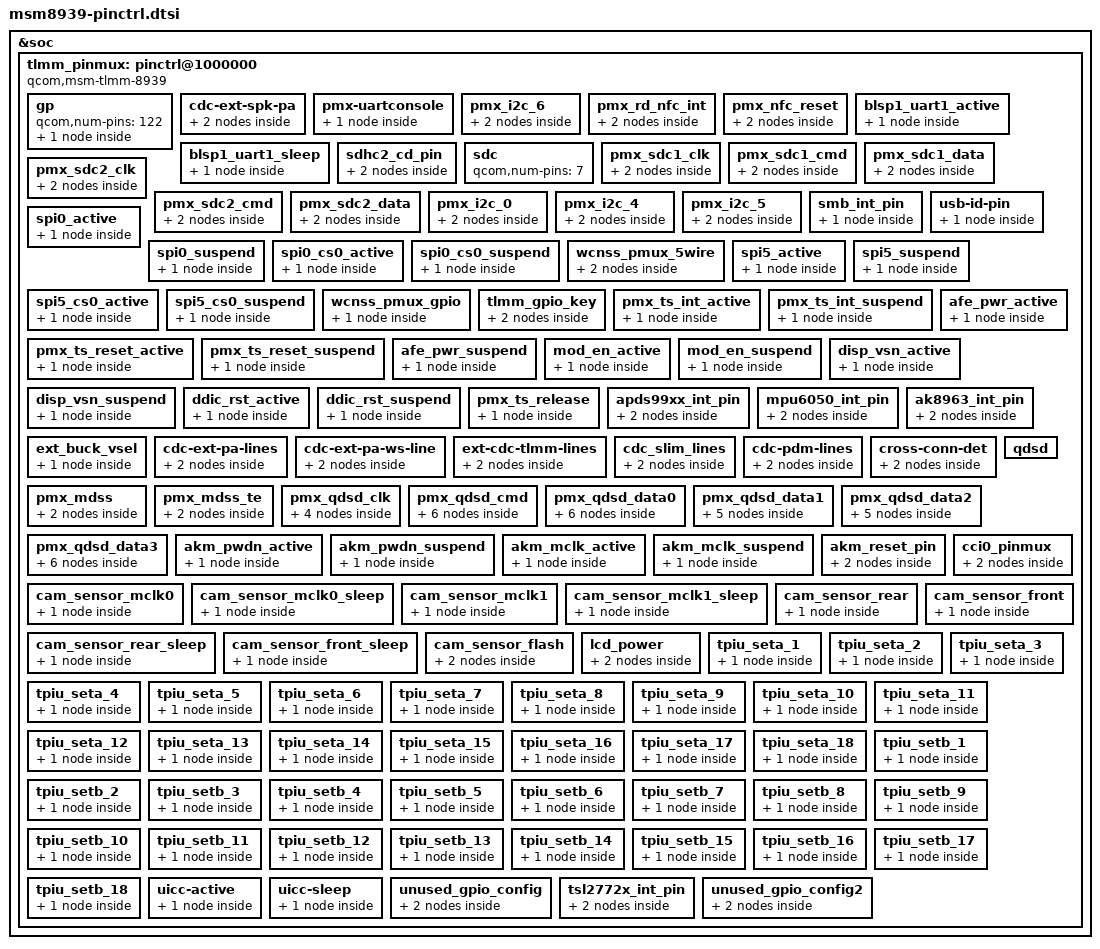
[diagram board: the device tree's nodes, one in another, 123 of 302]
/* Copyright (c) 2014-2015, The Linux Foundation. All rights reserved.
 *
 * This program is free software; you can redistribute it and/or modify
 * it under the terms of the GNU General Public License version 2 and
 * only version 2 as published by the Free Software Foundation.
 *
 * This program is distributed in the hope that it will be useful,
 * but WITHOUT ANY WARRANTY; without even the implied warranty of
 * MERCHANTABILITY or FITNESS FOR A PARTICULAR PURPOSE.  See the
 * GNU General Public License for more details.
 */

&soc {
	tlmm_pinmux: pinctrl@1000000 {
		compatible = "qcom,msm-tlmm-8939", "qcom,msm-tlmm-8916";
		reg = <0x1000000 0x300000>;
		interrupts = <0 208 0>;

		/*General purpose pins*/
		gp: gp {
			qcom,num-pins = <122>;
			#qcom,pin-cells = <1>;
			msm_gpio: msm_gpio {
				compatible = "qcom,msm-tlmm-gp";
				gpio-controller;
				#gpio-cells = <2>;
				interrupt-controller;
				#interrupt-cells = <2>;
				num_irqs = <122>;
			};
		};

		cdc-ext-spk-pa {
			qcom,pins = <&gp 0>;
			qcom,num-grp-pins = <1>;
			qcom,pin-func = <0>;
			label = "cdc-ext-spk-pa";
			cdc_ext_spk_pa_act: ext_spk_pa_on {
				drive-strength = <8>;
				output-low;
				bias-pull-none;
			};
			cdc_ext_spk_pa_sus: ext_spk_pa_off {
				drive-strength = <2>;
				bias-disable;
			};
		};

		pmx-uartconsole {
			qcom,pins = <&gp 4>, <&gp 5>;
			qcom,num-grp-pins = <2>;
			qcom,pin-func = <2>;
			label = "uart-console";
			uart_console_sleep: uart-console {
				drive-strength = <2>;
				bias-pull-down;
			};
		};

		pmx_i2c_6 {
			/* CLK, DATA */
			qcom,pins = <&gp 22>, <&gp 23>;
			qcom,num-grp-pins = <2>;
			qcom,pin-func = <2>;
			label = "pmx_i2c_6";
			/* active state */
			i2c_6_active: i2c_6_active{
				drive-strength = <2>; /* 2 MA */
				bias-disable; /* No PULL */
			};
			/* suspended state */
			i2c_6_sleep: i2c_6_sleep {
				drive-strength = <2>; /* 2 MA */
				bias-disable; /* No PULL */
			};
		};

		pmx_rd_nfc_int{
			qcom,pins = <&gp 21>;
			qcom,pin-func = <0>;
			qcom,num-grp-pins = <1>;
			label = "pmx_nfc_int";

			nfc_int_active: active {
				drive-strength = <6>;
				bias-pull-up;
			};

			nfc_int_suspend: suspend {
				drive-strength = <6>;
				bias-pull-up;
			};
		};

		pmx_nfc_reset{
			qcom,pins = <&gp 20>;
			qcom,pin-func = <0>;
			qcom,num-grp-pins = <1>;
			label = "pmx_nfc_disable";

			nfc_disable_active: active {
				drive-strength = <6>;
				bias-pull-up;
			};

			nfc_disable_suspend: suspend {
				drive-strength = <6>;
				bias-disable;
			};
		};

		blsp1_uart1_active {
			qcom,pins = <&gp 0>, <&gp 1>, <&gp 2>, <&gp 3>;
			qcom,num-grp-pins = <4>;
			qcom,pin-func = <2>;
			label = "blsp1_uart1_active";

			hsuart_active: default {
			        drive-strength = <16>;
			        bias-disable;
			};
		};

		blsp1_uart1_sleep {
			qcom,pins = <&gp 0>, <&gp 1>, <&gp 2>, <&gp 3>;
			qcom,num-grp-pins = <4>;
			qcom,pin-func = <0>;
			label = "blsp1_uart1_sleep";

			hsuart_sleep: sleep {
			        drive-strength = <2>;
			        bias-disable;
			};
		};

		sdhc2_cd_pin {
			qcom,pins = <&gp 38>;
			qcom,num-grp-pins = <1>;
			qcom,pin-func = <0>;
			label = "cd-gpio";
			sdc2_cd_on: cd_on {
				drive-strength = <2>;
				bias-pull-up;/* [PLATFORM]-MOD by TCTNB.YuBin, idol3 ds sd_cd_pin float need to pull up */
			};
			sdc2_cd_off: cd_off {
				drive-strength = <2>;
				bias-pull-up;/* [PLATFORM]-MOD by TCTNB.YuBin, idol3 ds sd_cd_pin float need to pull up */
			};
		};

		/* SDC pin type */
		sdc: sdc {
			/* 0-2 for sdc1 4-6 for sdc2 */
			qcom,num-pins = <7>;
			/* Order of pins */
			/* SDC1: CLK -> 0, CMD -> 1, DATA -> 2 */
			/* SDC2: CLK -> 4, CMD -> 5, DATA -> 6 */
			#qcom,pin-cells = <1>;
		};

		pmx_sdc1_clk {
			qcom,pins = <&sdc 0>;
			qcom,num-grp-pins = <1>;
			label = "sdc1-clk";
			sdc1_clk_on: clk_on {
				bias-disable; /* NO pull */
				drive-strength = <16>; /* 16 MA */
			};
			sdc1_clk_off: clk_off {
				bias-disable; /* NO pull */
				drive-strength = <2>; /* 2 MA */
			};
		};

		pmx_sdc1_cmd {
			qcom,pins = <&sdc 1>;
			qcom,num-grp-pins = <1>;
			label = "sdc1-cmd";
			sdc1_cmd_on: cmd_on {
				bias-pull-up; /* pull up */
				drive-strength = <10>; /* 10 MA */
			};
			sdc1_cmd_off: cmd_off {
				bias-pull-up; /* pull up */
				drive-strength = <2>; /* 2 MA */
			};
		};

		pmx_sdc1_data {
			qcom,pins = <&sdc 2>;
			qcom,num-grp-pins = <1>;
			label = "sdc1-data";
			sdc1_data_on: data_on {
				bias-pull-up; /* pull up */
				drive-strength = <10>; /* 10 MA */
			};
			sdc1_data_off: data_off {
				bias-pull-up; /* pull up */
				drive-strength = <2>; /* 2 MA */
			};
		};

		pmx_sdc2_clk {
			qcom,pins = <&sdc 4>;
			qcom,num-grp-pins = <1>;
			label = "sdc2-clk";
			sdc2_clk_on: clk_on {
				bias-disable; /* NO pull */
				drive-strength = <16>; /* 16 MA */
			};
			sdc2_clk_off: clk_off {
				bias-disable; /* NO pull */
				drive-strength = <2>; /* 2 MA */
			};
		};

		pmx_sdc2_cmd {
			qcom,pins = <&sdc 5>;
			qcom,num-grp-pins = <1>;
			label = "sdc2-cmd";
			sdc2_cmd_on: cmd_on {
				bias-pull-up; /* pull up */
				drive-strength = <10>; /* 10 MA */
			};
			sdc2_cmd_off: cmd_off {
				bias-pull-up; /* pull up */
				drive-strength = <2>; /* 2 MA */
			};
		};

		pmx_sdc2_data {
			qcom,pins = <&sdc 6>;
			qcom,num-grp-pins = <1>;
			label = "sdc2-data";
			sdc2_data_on: data_on {
				bias-pull-up; /* pull up */
				drive-strength = <10>; /* 10 MA */
			};
			sdc2_data_off: data_off {
				bias-pull-up; /* pull up */
				drive-strength = <2>; /* 2 MA */
			};
		};
		pmx_i2c_0 {
			/* CLK, DATA */
			qcom,pins = <&gp 7>, <&gp 6>;
			qcom,num-grp-pins = <2>;
			qcom,pin-func = <3>;
			label = "pmx_i2c_0";

			i2c_0_active: i2c_0_active {
				drive-strength = <2>; /* 2 MA */
				bias-disable;         /* No PULL */
			};

			i2c_0_sleep: i2c_0_sleep {
				drive-strength = <2>; /* 2 MA */
				bias-disable;	      /* No PULL */
			};
		};

		pmx_i2c_4 {
			qcom,pins = <&gp 14>, <&gp 15>; /* SDA, SCL */
			qcom,num-grp-pins = <2>;
			qcom,pin-func = <2>;
			label = "pmx_i2c_4";

			i2c_4_active: i2c_4_active {
				drive-strength = <2>;
				bias-disable;
			};

			i2c_4_sleep: i2c_4_sleep {
				drive-strength = <2>;
				bias-disable;
			};
		};

		pmx_i2c_5 {
			qcom,pins = <&gp 18>, <&gp 19>; /* SDA, SCL */
			qcom,num-grp-pins = <2>;
			qcom,pin-func = <2>;
			label = "pmx_i2c_5";

			i2c_5_active: i2c_5_active {
				drive-strength = <2>;
				bias-disable;
			};

			i2c_5_sleep: i2c_5_sleep {
				drive-strength = <2>;
				bias-disable;
			};
		};

		smb_int_pin {
			qcom,pins = <&gp 62>;
			qcom,num-grp-pins = <1>;
			qcom,pin-func = <0>;
			label = "smb1360_int_gpio";
			smb_int_default: smb_int_default {
				drive-strength = <2>;	/* 2 MA */
				bias-pull-up;		/* PULL UP*/
			};
		};

		usb-id-pin {
                        /*[PLATFORM]-Mod-BEGIN by TCTNB.Bin.Su, PR-883930, 2014/12/30, Idle power consumption is high in airplane*/
			//qcom,pins = <&gp 79>;/*NB.THW modify 2014/11/17*/
                        qcom,pins = <&gp 69>;
                        /* [PLATFORM]-Mod-END by TCTNB.Bin.Su */
			qcom,num-grp-pins = <1>;
			qcom,pin-func = <0>;
			label = "usb-id-pin";
			usbid_default: default {
				drive-strength = <8>;
				bias-pull-up;
			};
		};

		 spi0_active {
                        /* MOSI, MISO, CLK */
                        qcom,pins = <&gp 8>, <&gp 9>, <&gp 11>;
                        qcom,num-grp-pins = <3>;
                        qcom,pin-func = <1>;
                        label = "spi0-active";
                        /* active state */
                        spi0_default: spi0_default {
                                drive-strength = <12>; /* 12 MA */
                                bias-disable = <0>; /* No PULL */
                        };
                };

                spi0_suspend {
                        /* MOSI, MISO, CLK */
                        qcom,pins = <&gp 8>, <&gp 9>, <&gp 11>;
                        qcom,num-grp-pins = <3>;
                        qcom,pin-func = <0>;
                        label = "spi0-suspend";
                        /* suspended state */
                        spi0_sleep: spi0_sleep {
                                drive-strength = <2>; /* 2 MA */
			        bias-pull-down; /* PULL Down */
                        };
                };

                spi0_cs0_active {
                        /* CS */
                        qcom,pins = <&gp 10>;
                        qcom,num-grp-pins = <1>;
                        qcom,pin-func = <1>;
                        label = "spi0-cs0-active";
                        spi0_cs0_active: cs0_active {
                                drive-strength = <2>;
                                bias-disable = <0>;
                        };
                };

                spi0_cs0_suspend {
                        /* CS */
                        qcom,pins = <&gp 10>;
                        qcom,num-grp-pins = <1>;
                        qcom,pin-func = <0>;
                        label = "spi0-cs0-suspend";
                        spi0_cs0_sleep: cs0_sleep {
                                drive-strength = <2>;
                                bias-disable = <0>;
                        };
                };

		wcnss_pmux_5wire: wcnss_pmux_5wire {
			/* Uses general purpose pins */
			qcom,pins = <&gp 40>, <&gp 41>,
				    <&gp 42>, <&gp 43>,
				    <&gp 44>;
			qcom,num-grp-pins = <5>;
			qcom,pin-func = <1>;
			label = "wcnss_5wire_pins";
			/* Active configuration of bus pins */
			wcnss_default: wcnss_default {
			        drive-strength = <6>; /* 6 MA */
			        bias-pull-up; /* PULL UP */
			};
			wcnss_sleep: wcnss_sleep {
			        drive-strength = <2>; /* 2 MA */
			        bias-pull-down; /* PULL Down */
			};
		};

		spi5_active {
                        /* MOSI, MISO, CLK */
                        qcom,pins = <&gp 16>, <&gp 17>, <&gp 19>;
                        qcom,num-grp-pins = <3>;
                        qcom,pin-func = <1>;
                        label = "spi5-active";
                        /* active state */
                        spi5_default: spi5_default {
                                drive-strength = <16>; /* 16 MA */
                                bias-disable = <0>; /* No PULL */
                        };
                };

                spi5_suspend {
                        /* MOSI, MISO, CLK */
                        qcom,pins = <&gp 16>, <&gp 17>, <&gp 19>;
                        qcom,num-grp-pins = <3>;
                        qcom,pin-func = <0>;
                        label = "spi5-suspend";
                        /* suspended state */
                        spi5_sleep: spi5_sleep {
                                drive-strength = <2>; /* 2 MA */
                                bias-disable = <0>; /* No PULL */
                        };
                };

                spi5_cs0_active {
                        /* CS */
                        qcom,pins = <&gp 18>;
                        qcom,num-grp-pins = <1>;
                        qcom,pin-func = <1>;
                        label = "spi5-cs0-active";
                        spi5_cs0_active: cs0_active {
                                drive-strength = <2>;
                                bias-disable = <0>;
                        };
                };

                spi5_cs0_suspend {
                        /* CS */
                        qcom,pins = <&gp 18>;
                        qcom,num-grp-pins = <1>;
                        qcom,pin-func = <0>;
                        label = "spi5-cs0-suspend";
                        spi5_cs0_sleep: cs0_sleep {
                                drive-strength = <2>;
                                bias-disable = <0>;
                        };
                };

		wcnss_pmux_gpio: wcnss_pmux_gpio {
			/* Uses general purpose pins */
			qcom,pins = <&gp 40>, <&gp 41>,
				    <&gp 42>, <&gp 43>,
				    <&gp 44>;
			qcom,num-grp-pins = <5>;
			qcom,pin-func = <0>;
			label = "wcnss_5gpio_pins";
			/* Active configuration of bus pins */
			wcnss_gpio_default: wcnss_gpio_default {
			        drive-strength = <6>; /* 6 MA */
			        bias-pull-up; /* PULL UP */
			};
		};

		tlmm_gpio_key {
			qcom,pins = <&gp 107>, <&gp 98>;  /* <&gp 36>, <&gp 108>, <&gp 109> */
			qcom,pin-func = <0>;
			qcom,num-grp-pins = <2>;
			label = "tlmm_gpio_key";
			gpio_key_active: gpio_key_active {
				drive-strength = <2>;
				bias-pull-up;
			};
			gpio_key_suspend: gpio_key_suspend {
				drive-strength = <2>;
				bias-pull-up;
			};
		};

		/* add pingrp for touchscreen */
		pmx_ts_int_active {
			qcom,pins = <&gp 13>;
			qcom,pin-func = <0>;
			qcom,num-grp-pins = <1>;
			label = "pmx_ts_int_active";

			ts_int_active: ts_int_active {
				drive-strength = <16>;
				bias-pull-up;
			};
		};

		pmx_ts_int_suspend {
			qcom,pins = <&gp 13>;
			qcom,pin-func = <0>;
			qcom,num-grp-pins = <1>;
			label = "pmx_ts_int_suspend";

			ts_int_suspend: ts_int_suspend {
				drive-strength = <2>;
				bias-pull-down;
			};
		};

		pmx_ts_reset_active {
			qcom,pins = <&gp 12>;
			qcom,pin-func = <0>;
			qcom,num-grp-pins = <1>;
			label = "pmx_ts_reset_active";

			ts_reset_active: ts_reset_active {
				drive-strength = <16>;
				bias-pull-up;
			};
		};

		pmx_ts_reset_suspend {
			qcom,pins = <&gp 12>;
			qcom,pin-func = <0>;
			qcom,num-grp-pins = <1>;
			label = "pmx_ts_reset_suspend";

			ts_reset_suspend: ts_reset_suspend {
				drive-strength = <2>;
				bias-pull-down;
			};
		};

		afe_pwr_active {
			qcom,pins = <&gp 75>;
			qcom,pin-func = <0>;
			qcom,num-grp-pins = <1>;
			label = "afe_active";

			afe_pwr_active: afe_pwr_active {
				drive-strength = <16>;
				output-high;
			};
		};

		afe_pwr_suspend {
			qcom,pins = <&gp 75>;
			qcom,pin-func = <0>;
			qcom,num-grp-pins = <1>;
			label = "afe_suspend";

			afe_pwr_suspend: afe_pwr_suspend {
				drive-strength = <2>;
				output-low;
			};
		};

		mod_en_active {
			qcom,pins = <&gp 97>;
			qcom,pin-func = <0>;
			qcom,num-grp-pins = <1>;
			label = "mod_en_active";

			mod_en_active: mod_en_active {
				drive-strength = <16>;
				output-high;
			};
		};

		mod_en_suspend {
			qcom,pins = <&gp 97>;
			qcom,pin-func = <0>;
			qcom,num-grp-pins = <1>;
			label = "mod_en_suspend";

			mod_en_suspend: mod_en_suspend {
				drive-strength = <2>;
				output-low;
			};
		};

		disp_vsn_active {
			qcom,pins = <&gp 77>;
			qcom,pin-func = <0>;
			qcom,num-grp-pins = <1>;
			label = "disp_vsn_active";

			disp_vsn_active: disp_vsn_active {
				drive-strength = <16>;
				output-high;
			};
		};

		disp_vsn_suspend {
			qcom,pins = <&gp 77>;
			qcom,pin-func = <0>;
			qcom,num-grp-pins = <1>;
			label = "disp_vsn_suspend";

			disp_vsn_suspend: disp_vsn_suspend {
				drive-strength = <2>;
				output-low;
			};
		};

		ddic_rst_active {
			qcom,pins = <&gp 25>;
			qcom,pin-func = <0>;
			qcom,num-grp-pins = <1>;
			label = "ddic_rst_active";

			ddic_rst_active: ddic_rst_active {
				drive-strength = <16>;
				output-high;
			};
		};

		ddic_rst_suspend {
			qcom,pins = <&gp 25>;
			qcom,pin-func = <0>;
			qcom,num-grp-pins = <1>;
			label = "ddic_rst_suspend";

			ddic_rst_suspend: ddic_rst_suspend {
				drive-strength = <2>;
				output-low;
			};
		};

		pmx_ts_release {
			qcom,pins = <&gp 13>, <&gp 12>;
			qcom,num-grp-pins = <2>;
			label = "pmx_ts_release";

			ts_release: ts_release {
				drive-strength = <2>;
				bias-pull-down;
			};
		};

		apds99xx_int_pin {
			/* Ambient light and proximity sensor apds9930 and apds9900 */
			qcom,pins = <&gp 113>;
			qcom,pin-func = <0>;
			qcom,num-grp-pins = <1>;
			label = "apds99xx-irq";
			apds99xx_default: apds99xx_default {
				drive-strength = <6>;
				bias-pull-up;
			};
			apds99xx_sleep: apds99xx_sleep {
				drive-strength = <2>;
				bias-pull-down;
			};
		};

		mpu6050_int_pin {
			/* Gyroscope and accelerometer sensor combo */
			qcom,pins = <&gp 115>;
			qcom,pin-func = <0>;
			qcom,num-grp-pins = <1>;
			label = "mpu6050-irq";
			mpu6050_default: mpu6050_default {
				drive-strength = <6>;
				bias-pull-up;
			};
			mpu6050_sleep: mpu6050_sleep {
				drive-strength = <2>;
				bias-pull-down;
			};
		};

		ak8963_int_pin {
			qcom,pins = <&gp 69>;
			qcom,pin-func = <0>;
			qcom,num-grp-pins = <1>;
			label = "ak8963-irq";
			ak8963_default: ak8963_default {
				drive-strength = <6>;
				bias-pull-up;
			};
			ak8963_sleep: ak8963_sleep {
				drive-strength = <2>;
				bias-pull-down;
			};
		};

		ext_buck_vsel {
			qcom,pins = <&gp 111>;
			qcom,num-grp-pins = <1>;
			qcom,pin-func = <0>;
			label = "ext-buck-vsel";

			ext_buck_vsel_default: vsel0 {
				drive-strength = <2>;
			};
		};
		/*NB.THW 2014/11/17 add for FR.789207*/
		cdc-ext-pa-lines {
			qcom,pins = <&gp 113>,
					<&gp 115>;
			qcom,num-grp-pins = <2>;
			qcom,pin-func = <1>;
			label = "cdc-ext-pa-lines";
			cdc_ext_pa_act: ext_pa_on {
				drive-strength = <8>;
				bias-pull-none;
			};
			cdc_ext_pa_sus: ext_pa_off {
				drive-strength = <2>;
				bias-disable;
			};
		};

		cdc-ext-pa-ws-line {
			qcom,pins = <&gp 110>;
			qcom,num-grp-pins = <1>;
			qcom,pin-func = <2>;
			label = "cdc-ext-pa-ws-line";
			cdc_ext_pa_ws_act: ext_pa_on {
				drive-strength = <8>;
				bias-pull-none;
			};
			cdc_ext_pa_ws_sus: ext_pa_off {
				drive-strength = <2>;
				bias-disable;
			};
		};
/*NB.THW 2014/11/17 end*/
		ext-cdc-tlmm-lines {
			qcom,pins = <&gp 112>, <&gp 117>,/*NB.THW 2014/11/17 remove for FR.789207*/
					<&gp 118>, <&gp 119>;
			qcom,num-grp-pins = <4>;/*NB.THW 2014/11/17 remove for FR.789207*/
			qcom,pin-func = <1>;
			label = "ext-cdc-tlmm-lines";
			ext_cdc_tlmm_lines_act: tlmm_lines_on {
				drive-strength = <8>;
			};
			ext_cdc_tlmm_lines_sus: tlmm_lines_off {
				drive-strength = <2>;
				bias-disable;
			};
		};

		cdc_slim_lines {
			qcom,pins = <&gp 63>;
			qcom,num-grp-pins = <1>;
			qcom,pin-func = <2>;
			label = "cdc_slim_lines";
			cdc_slim_lines_act: slim_lines_on {
				drive-strength = <8>;
				bias-pull-none;
				output-high;
			};
			cdc_slim_lines_sus: slim_lines_off {
				drive-strength = <2>;
				bias-disable;
			};
		};

		cdc-pdm-lines {
			qcom,pins = <&gp 63>, <&gp 64>, <&gp 65>,
					<&gp 66>, <&gp 67>, <&gp 68>;
			qcom,num-grp-pins = <6>;
			qcom,pin-func = <1>;
			label = "cdc-pdm-lines";
			cdc_pdm_lines_act: pdm_lines_on {
				drive-strength = <8>;
				bias-pull-none;
			};
			cdc_pdm_lines_sus: pdm_lines_off {
				drive-strength = <2>;
				bias-pull-down;
			};
		};

		cross-conn-det {
			qcom,pins = <&gp 120>;
			qcom,num-grp-pins = <1>;
			qcom,pin-func = <0>;
			label = "cross-conn-det-sw";
			cross_conn_det_act: lines_on {
				drive-strength = <8>;
				output-low;
				bias-pull-down;
			};
			cross_conn_det_sus: lines_off {
				drive-strength = <2>;
				bias-disable;
			};
		};

		pmx_mdss: pmx_mdss {
			label = "mdss-pins";
			qcom,pin-func = <0>;
			/*MODIFIED-BEGIN by jianeng.yuan, 2016-04-14,BUG-1941671*/
			qcom,num-grp-pins = <1>;
			qcom,pins = <&gp 25>;
			/*MODIFIED-END by jianeng.yuan,BUG-1941671*/
			mdss_dsi_active: active {
				drive-strength = <8>; /* 8 mA */
				bias-disable = <0>; /* no pull */
			};
			mdss_dsi_suspend: suspend {
				drive-strength = <2>; /* 2 mA */
				bias-pull-down; /* pull down */
			};
		};

		pmx_mdss_te: pmx_mdss_te {
			label = "mdss-te-pin";
			/*MODIFIED-BEGIN by jianeng.yuan, 2016-04-14,BUG-1941671*/
			qcom,num-grp-pins = <1>;
			qcom,pins = <&gp 24>;
			/*MODIFIED-END by jianeng.yuan,BUG-1941671*/
			qcom,pin-func = <1>;
			mdss_te_active: active {
				drive-strength = <2>; /* 2 mA */
				bias-pull-down; /* pull down */
				input-debounce = <0>;
			};
			mdss_te_suspend: suspend {
				drive-strength = <2>; /* 2 mA */
				bias-pull-down; /* pull down */
				input-debounce = <0>;
			};
		};

		/* QDSD pin type */
		qdsd: qdsd {
			qcom,pin-type-qdsd;
			/* 0-> clk, 1 -> cmd, 2->data0, 3->data1, 4->data2, 5->data3 */
			qcom,num-pins = <6>;

			#qcom,pin-cells = <1>;
		};

		pmx_qdsd_clk {
			qcom,pins = <&qdsd 0>;
			qcom,num-grp-pins = <1>;
			label = "qdsd-clk";
			qdsd_clk_sdcard: clk_sdcard {
				bias-disable; /* NO pull */
				drive-strength = <7>; /* 7 MA */
			};
			qdsd_clk_trace: clk_trace {
				bias-pull-down; /* pull down */
				drive-strength = <0>; /* 0 MA */
			};
			qdsd_clk_swdtrc: clk_swdtrc {
				bias-pull-down; /* pull down */
				drive-strength = <0>; /* 0 MA */
			};
			qdsd_clk_spmi: clk_spmi {
				bias-pull-down; /* pull down */
				drive-strength = <0>; /* 0 MA */
			};
		};

		pmx_qdsd_cmd {
			qcom,pins = <&qdsd 1>;
			qcom,num-grp-pins = <1>;
			label = "qdsd-cmd";
			qdsd_cmd_sdcard: cmd_sdcard {
				bias-pull-down; /* pull down */
				drive-strength = <3>; /* 3 MA */
			};
			qdsd_cmd_trace: cmd_trace {
				bias-pull-down; /* pull down */
				drive-strength = <0>; /* 0 MA */
			};
			qdsd_cmd_swduart: cmd_uart {
				bias-pull-up; /* pull up */
				drive-strength = <0>; /* 0 MA */
			};
			qdsd_cmd_swdtrc: cmd_swdtrc {
				bias-pull-up; /* pull up */
				drive-strength = <0>; /* 0 MA */
			};
			qdsd_cmd_jtag: cmd_jtag {
				bias-disable; /* NO pull */
				drive-strength = <3>; /* 3 MA */
			};
			qdsd_cmd_spmi: cmd_spmi {
				bias-pull-down; /* pull down */
				drive-strength = <4>; /* 4 MA */
			};
		};

		pmx_qdsd_data0 {
			qcom,pins = <&qdsd 2>;
			qcom,num-grp-pins = <1>;
			label = "qdsd-data0";
			qdsd_data0_sdcard: data0_sdcard {
				bias-pull-down; /* pull down */
				drive-strength = <3>; /* 3 MA */
			};
			qdsd_data0_trace: data0_trace {
				bias-pull-down; /* pull down */
				drive-strength = <0>; /* 0 MA */
			};
			qdsd_data0_swduart: data0_uart {
				bias-pull-down; /* pull down */
				drive-strength = <0>; /* 0 MA */
			};
			qdsd_data0_swdtrc: data0_swdtrc {
				bias-pull-down; /* pull down */
				drive-strength = <0>; /* 0 MA */
			};
			qdsd_data0_jtag: data0_jtag {
				bias-pull-up; /* pull up */
				drive-strength = <0>; /* 0 MA */
			};
			qdsd_data0_spmi: data0_spmi {
				bias-pull-down; /* pull down */
				drive-strength = <0>; /* 0 MA */
			};
		};

		pmx_qdsd_data1 {
			qcom,pins = <&qdsd 3>;
			qcom,num-grp-pins = <1>;
			label = "qdsd-data1";
			qdsd_data1_sdcard: data1_sdcard {
				bias-pull-down; /* pull down */
				drive-strength = <3>; /* 3 MA */
			};
			qdsd_data1_trace: data1_trace {
				bias-pull-down; /* pull down */
				drive-strength = <0>; /* 0 MA */
			};
			qdsd_data1_swduart: data1_uart {
				bias-pull-down; /* pull down */
				drive-strength = <0>; /* 0 MA */
			};
			qdsd_data1_swdtrc: data1_swdtrc {
				bias-pull-down; /* pull down */
				drive-strength = <0>; /* 0 MA */
			};
			qdsd_data1_jtag: data1_jtag {
				bias-pull-down; /* pull down */
				drive-strength = <0>; /* 0 MA */
			};
		};

		pmx_qdsd_data2 {
			qcom,pins = <&qdsd 4>;
			qcom,num-grp-pins = <1>;
			label = "qdsd-data2";
			qdsd_data2_sdcard: data2_sdcard {
				bias-pull-down; /* pull down */
				drive-strength = <3>; /* 3 MA */
			};
			qdsd_data2_trace: data2_trace {
				bias-pull-down; /* pull down */
				drive-strength = <0>; /* 0 MA */
			};
			qdsd_data2_swduart: data2_uart {
				bias-pull-down; /* pull down */
				drive-strength = <0>; /* 0 MA */
			};
			qdsd_data2_swdtrc: data2_swdtrc {
				bias-pull-down; /* pull down */
				drive-strength = <0>; /* 0 MA */
			};
			qdsd_data2_jtag: data2_jtag {
				bias-pull-up; /* pull up */
				drive-strength = <3>; /* 3 MA */
			};
		};

		pmx_qdsd_data3 {
			qcom,pins = <&qdsd 5>;
			qcom,num-grp-pins = <1>;
			label = "qdsd-data3";
			qdsd_data3_sdcard: data3_sdcard {
				bias-pull-down; /* pull down */
				drive-strength = <3>; /* 3 MA */
			};
			qdsd_data3_trace: data3_trace {
				bias-pull-down; /* pull down */
				drive-strength = <0>; /* 0 MA */
			};
			qdsd_data3_swduart: data3_uart {
				bias-pull-up; /* pull up */
				drive-strength = <0>; /* 0 MA */
			};
			qdsd_data3_swdtrc: data3_swdtrc {
				bias-pull-up; /* pull up */
				drive-strength = <0>; /* 0 MA */
			};
			qdsd_data3_jtag: data3_jtag {
				bias-pull-up; /* pull up */
				drive-strength = <0>; /* 0 MA */
			};
			qdsd_data3_spmi: data3_spmi {
				bias-pull-down; /* pull down */
				drive-strength = <3>; /* 3 MA */
			};
		};
/*NB.THW 2014/11/17 add for FR.789207*/

/* [PLATFORM]-Add-BEGIN by TCTNB.HJ, 2014/11/18, HIFI*/
         akm_pwdn_active {
             qcom,pins = <&gp 101>;
             qcom,pin-func = <0>;
             qcom,num-grp-pins = <1>;
             label = "akm_pwdn_active";
             akm_pwdn_active: akm_pwdn_active {
                 drive-strength = <16>;
                 output-high;
             };
         };

         akm_pwdn_suspend {
             qcom,pins = <&gp 101>;
             qcom,pin-func = <0>;
             qcom,num-grp-pins = <1>;
             label = "akm_pwdn_suspend";
             akm_pwdn_suspend: akm_pwdn_suspend {
                 drive-strength = <2>;
                 output-low;
             };
         };

        akm_mclk_active {
             qcom,pins = <&gp 116>;
             qcom,pin-func = <0>;
             qcom,num-grp-pins = <1>;
             label = "akm_mclk_active";
             akm_mclk_active: akm_mclk_active {
                 drive-strength = <2>;
                 bias-pull-down;
                 output-low;
             };
         };

         akm_mclk_suspend {
             qcom,pins = <&gp 116>;
             qcom,pin-func = <0>;
             qcom,num-grp-pins = <1>;
             label = "akm_mclk_suspend";
             akm_mclk_suspend: akm_mclk_suspend {
                 drive-strength = <2>;
                 bias-pull-down;
                 output-low;
             };
         };
/*
        ak4375_dac_ldo_ctl_active {
			qcom,pins = <&gp 102>;
			qcom,pin-func = <0>;
			qcom,num-grp-pins = <1>;
			label = "ak4375_dac_ldo_ctl_active";

			dac_ldo_ctl_active: dac_ldo_ctl_active {
				drive-strength = <16>;
				bias-pull-up;
			};
		};

        ak4375_dac_ldo_ctl_suspend {
			qcom,pins = <&gp 102>;
			qcom,pin-func = <0>;
			qcom,num-grp-pins = <1>;
			label = "ak4375_dac_ldo_ctl_suspend";

			dac_ldo_ctl_suspend: dac_ldo_ctl_suspend  {
				drive-strength = <2>;
				bias-pull-down;
			};
		};
*/
/* [PLATFORM]-Add-END by TCTNB.HJ*/

/*MODIFIED-BEGIN by jianeng.yuan, 2016-04-14,BUG-1941671*/
/*[BUFFIX]-Add-bgein  by TCTNB.XQJ, PR-797187,789423, 797185,2014/11/14,finish sensors drirver*/
	akm_reset_pin {
		qcom,pins = <&gp 100>;
		qcom,pin-func = <0>;
		qcom,num-grp-pins = <1>;
		label = "akm_reset_pin";
		akm_default: akm_default {
			drive-strength = <6>;
			bias-pull-up;
		};
		akm_sleep: akm_sleep {
			drive-strength = <2>;
			bias-pull-down;
		};
	};
/*[BUFFIX]-End- by TCTNB.XQJ*/
/*MODIFIED-END by jianeng.yuan,BUG-1941671*/

/*NB.THW 2014/11/17 end*/
		cci0_pinmux {
			/* CLK, DATA */
			qcom,pins = <&gp 29>, <&gp 30>;
			qcom,num-grp-pins = <2>;
			qcom,pin-func = <1>;
			label = "cci0";
			/* active state */
			cci0_default: default {
				drive-strength = <2>; /* 2 MA */
				bias-disable = <0>; /* No PULL */
			};
			/*suspended state */
			cci0_sleep: sleep {
				drive-strength = <2>; /* 2 MA */
				bias-disable = <0>; /* No PULL */
			};
		};

		cam_sensor_mclk0 {
			/* MCLK */
			qcom,pins = <&gp 26>;
			qcom,num-grp-pins = <1>;
			qcom,pin-func = <1>;
			label = "cam-sensor-mclk0";
			/* active state */
			cam_sensor_mclk0_default: default {
				drive-strength = <2>; /* 2 MA */
				bias-disable = <0>; /* No PULL */
			};
                };

		cam_sensor_mclk0_sleep {
			/* MCLK */
			qcom,pins = <&gp 26>;
			qcom,num-grp-pins = <1>;
			label = "cam-sensor-mclk0-sleep";
			/*suspend state */
			cam_sensor_mclk0_sleep: sleep {
				drive-strength = <2>; /* 2 MA */
				bias-pull-down; /* PULL DOWN */
			};
		};
		cam_sensor_mclk1 {
			/* MCLK */
			qcom,pins = <&gp 27>;
			qcom,num-grp-pins = <1>;
			qcom,pin-func = <1>;
			label = "cam-sensor-mclk1";
			/* active state */
			cam_sensor_mclk1_default: default {
				drive-strength = <2>; /* 2 MA */
				bias-disable = <0>; /* No PULL */
			};
                };

		cam_sensor_mclk1_sleep {
			/* MCLK */
			qcom,pins = <&gp 27>;
			qcom,num-grp-pins = <1>;
			label = "cam-sensor-mclk1-sleep";
			/*suspend state */
			cam_sensor_mclk1_sleep: sleep {
				drive-strength = <2>; /* 2 MA */
				bias-pull-down; /* PULL DOWN */
			};
		};

		cam_sensor_rear {
			/* RESET, STANDBY */
			//qcom,pins =  <&gp 35>, <&gp 94>;
			//qcom,num-grp-pins = <2>;
			qcom,pins =  <&gp 35>, <&gp 94>, <&gp 16>, <&gp 17>; //17 also used by front camera
			qcom,num-grp-pins = <4>;
			qcom,pin-func = <0>;
			label = "cam-sensor-rear";
			/* active state */
			cam_sensor_rear_default: default {
				drive-strength = <4>; /* 4 MA */
				bias-disable = <0>; /* No PULL */
			};
		};

		cam_sensor_rear_sleep {
			/* RESET, STANDBY */
			qcom,pins =  <&gp 35>, <&gp 94>, <&gp 16>, <&gp 17>; //17 also used by front camera
			qcom,num-grp-pins = <4>;
			qcom,pin-func = <0>;
			label = "cam-sensor-rear-sleep";
			/*suspend state */
			cam_sensor_rear_sleep: sleep {
				drive-strength = <2>; /* 2 MA */
				bias-pull-down; /* PULL DOWN */
			};
		};

		cam_sensor_front {
			/* RESET, STANDBY */
			/*MODIFIED-BEGIN by jianeng.yuan, 2016-04-14,BUG-1941671*/
			qcom,pins = <&gp 28>, <&gp 33>, <&gp 109>;//, <&gp 17>;//17 also used by rear camera
			qcom,num-grp-pins = <3>;
			/*MODIFIED-END by jianeng.yuan,BUG-1941671*/
			qcom,pin-func = <0>;
			label = "cam_sensor_front";
			/* active state */
			cam_sensor_front_default: default {
				drive-strength = <2>; /* 2 MA */
				bias-disable = <0>; /* No PULL */
			};
		};

		cam_sensor_front_sleep {
			/* RESET, STANDBY */
			/*MODIFIED-BEGIN by jianeng.yuan, 2016-04-14,BUG-1941671*/
			qcom,pins = <&gp 28>, <&gp 33>, <&gp 109>;//, <&gp 17>;////17 also used by rear camera
			qcom,num-grp-pins = <3>;
			/*MODIFIED-END by jianeng.yuan,BUG-1941671*/
			qcom,pin-func = <0>;
			label = "cam_sensor_front_sleep";
			/*suspend state */
			cam_sensor_front_sleep: sleep {
				drive-strength = <2>; /* 2 MA */
				bias-pull-down = <0>; /* PULL DOWN */
			};
		};

		cam_sensor_flash {
			/* FLSH_RESET,FLASH_EN,FLASH_NOW */
			/*[PLATFORM]-Mod-BEGIN by TCTNB.WJ, 2015/1/4, conflict with HALL */
			//qcom,pins = <&gp 31>,<&gp 32> ;   /* <&gp 36> */ //ljtao delete
			qcom,pins = <&gp 2>,<&gp 32> ;
			qcom,num-grp-pins = <2>;   /* <3>; */
			/*[PLATFORM]-Mod-End */
			qcom,pin-func = <0>;
			label = "cam_sensor_flash";
			/* active state */
			cam_sensor_flash_default: default {
				drive-strength = <2>; /* 2 MA */
				bias-disable = <0>; /* No PULL */
			};
			/*suspended state */
			cam_sensor_flash_sleep: sleep {
				drive-strength = <2>; /* 2 MA */
				bias-pull-down = <0>; /* PULL DOWN */
			};
		};

/* [PLATFORM]-Add-BEGIN by TCTNB.CY, PR-887679, 2014/12/31, lcd power ic gpio configure*/
		lcd_power {
			/* LCD power IC gpio configure*/
			qcom,pins =  <&gp 105>, <&gp 106>;
			qcom,num-grp-pins = <2>;
			qcom,pin-func = <0>;
			label = "lcd_power";
/* [PLATFORM]-Mod-BEGIN by TCTNB.CY, CR-874734, 2015/1/28, modify for LCD power ic enable gpio output*/
			/* active state */
			lcd_power_active: active {
				drive-strength = <2>; /* 2 MA */
				bias-pull-up; /* pull up */
				output-high;
			};

			lcd_power_suspend: suspend {
				drive-strength = <2>; /* 2 mA */
				bias-pull-down; /* pull down */
				output-low;
			};
/* [PLATFORM]-Mod-END by TCTNB.CY,  2015/1/28*/

		};
/* [PLATFORM]-Add-END by TCTNB.CY, 2014/12/31*/

		/* CoreSight */
		tpiu_seta_1 {
			qcom,pins = <&gp 8>;
			qcom,num-grp-pins = <1>;
			qcom,pin-func = <3>;
			label = "tpiu-seta-1";
			seta_1: seta {
				drive-strength = <16>;
				bias-disable;
			};
		};

		tpiu_seta_2 {
			qcom,pins = <&gp 9>;
			qcom,num-grp-pins = <1>;
			qcom,pin-func = <2>;
			label = "tpiu-seta-2";
			seta_2: seta {
				drive-strength = <16>;
				bias-disable;
			};
		};

		tpiu_seta_3 {
			qcom,pins = <&gp 10>;
			qcom,num-grp-pins = <1>;
			qcom,pin-func = <3>;
			label = "tpiu-seta-3";
			seta_3: seta {
				drive-strength = <16>;
				bias-disable;
			};
		};

		tpiu_seta_4 {
			qcom,pins = <&gp 39>;
			qcom,num-grp-pins = <1>;
			qcom,pin-func = <2>;
			label = "tpiu-seta-4";
			seta_4: seta {
				drive-strength = <16>;
				bias-disable;
			};
		};

		tpiu_seta_5 {
			qcom,pins = <&gp 40>;
			qcom,num-grp-pins = <1>;
			qcom,pin-func = <2>;
			label = "tpiu-seta-5";
			seta_5: seta {
				drive-strength = <16>;
				bias-disable;
			};
		};

		tpiu_seta_6 {
			qcom,pins = <&gp 41>;
			qcom,num-grp-pins = <1>;
			qcom,pin-func = <2>;
			label = "tpiu-seta-6";
			seta_6: seta {
				drive-strength = <16>;
				bias-disable;
			};
		};

		tpiu_seta_7 {
			qcom,pins = <&gp 42>;
			qcom,num-grp-pins = <1>;
			qcom,pin-func = <2>;
			label = "tpiu-seta-7";
			seta_7: seta {
				drive-strength = <16>;
				bias-disable;
			};
		};

		tpiu_seta_8 {
			qcom,pins = <&gp 43>;
			qcom,num-grp-pins = <1>;
			qcom,pin-func = <3>;
			label = "tpiu-seta-8";
			seta_8: seta {
				drive-strength = <16>;
				bias-disable;
			};
		};

		tpiu_seta_9 {
			qcom,pins = <&gp 45>;
			qcom,num-grp-pins = <1>;
			qcom,pin-func = <3>;
			label = "tpiu-seta-9";
			seta_9: seta {
				drive-strength = <16>;
				bias-disable;
			};
		};

		tpiu_seta_10 {
			qcom,pins = <&gp 46>;
			qcom,num-grp-pins = <1>;
			qcom,pin-func = <2>;
			label = "tpiu-seta-10";
			seta_10: seta {
				drive-strength = <16>;
				bias-disable;
			};
		};

		tpiu_seta_11 {
			qcom,pins = <&gp 47>;
			qcom,num-grp-pins = <1>;
			qcom,pin-func = <3>;
			label = "tpiu-seta-11";
			seta_11: seta {
				drive-strength = <16>;
				bias-disable;
			};
		};

		tpiu_seta_12 {
			qcom,pins = <&gp 48>;
			qcom,num-grp-pins = <1>;
			qcom,pin-func = <2>;
			label = "tpiu-seta-12";
			seta_12: seta {
				drive-strength = <16>;
				bias-disable;
			};
		};

		tpiu_seta_13 {
			qcom,pins = <&gp 62>;
			qcom,num-grp-pins = <1>;
			qcom,pin-func = <1>;
			label = "tpiu-seta-13";
			seta_13: seta {
				drive-strength = <16>;
				bias-disable;
			};
		};

		tpiu_seta_14 {
			qcom,pins = <&gp 69>;
			qcom,num-grp-pins = <1>;
			qcom,pin-func = <2>;
			label = "tpiu-seta-14";
			seta_14: seta {
				drive-strength = <16>;
				bias-disable;
			};
		};

		tpiu_seta_15 {
			qcom,pins = <&gp 112>;
			qcom,num-grp-pins = <1>;
			qcom,pin-func = <6>;
			label = "tpiu-seta-15";
			seta_15: seta {
				drive-strength = <16>;
				bias-disable;
			};
		};

		tpiu_seta_16 {
			qcom,pins = <&gp 113>;
			qcom,num-grp-pins = <1>;
			qcom,pin-func = <9>;
			label = "tpiu-seta-16";
			seta_16: seta {
				drive-strength = <16>;
				bias-disable;
			};
		};

		tpiu_seta_17 {
			qcom,pins = <&gp 114>;
			qcom,num-grp-pins = <1>;
			qcom,pin-func = <8>;
			label = "tpiu-seta-17";
			seta_17: seta {
				drive-strength = <16>;
				bias-disable;
			};
		};

		tpiu_seta_18 {
			qcom,pins = <&gp 115>;
			qcom,num-grp-pins = <1>;
			qcom,pin-func = <8>;
			label = "tpiu-seta-18";
			seta_18: seta {
				drive-strength = <16>;
				bias-disable;
			};
		};

		tpiu_setb_1 {
			qcom,pins = <&gp 4>;
			qcom,num-grp-pins = <1>;
			qcom,pin-func = <5>;
			label = "tpiu-setb-1";
			setb_1: setb {
				drive-strength = <16>;
				bias-disable;
			};
		};

		tpiu_setb_2 {
			qcom,pins = <&gp 5>;
			qcom,num-grp-pins = <1>;
			qcom,pin-func = <5>;
			label = "tpiu-setb-2";
			setb_2: setb {
				drive-strength = <16>;
				bias-disable;
			};
		};

		tpiu_setb_3 {
			qcom,pins = <&gp 26>;
			qcom,num-grp-pins = <1>;
			qcom,pin-func = <7>;
			label = "tpiu-setb-3";
			setb_3: setb {
				drive-strength = <16>;
				bias-disable;
			};
		};

		tpiu_setb_4 {
			qcom,pins = <&gp 27>;
			qcom,num-grp-pins = <1>;
			qcom,pin-func = <10>;
			label = "tpiu-setb-4";
			setb_4: setb {
				drive-strength = <16>;
				bias-disable;
			};
		};

		tpiu_setb_5 {
			qcom,pins = <&gp 28>;
			qcom,num-grp-pins = <1>;
			qcom,pin-func = <7>;
			label = "tpiu-setb-5";
			setb_5: setb {
				drive-strength = <16>;
				bias-disable;
			};
		};

		tpiu_setb_6 {
			qcom,pins = <&gp 29>;
			qcom,num-grp-pins = <1>;
			qcom,pin-func = <7>;
			label = "tpiu-setb-6";
			setb_6: setb {
				drive-strength = <16>;
				bias-disable;
			};
		};

		tpiu_setb_7 {
			qcom,pins = <&gp 30>;
			qcom,num-grp-pins = <1>;
			qcom,pin-func = <9>;
			label = "tpiu-setb-7";
			setb_7: setb {
				drive-strength = <16>;
				bias-disable;
			};
		};

		tpiu_setb_8 {
			qcom,pins = <&gp 31>;
			qcom,num-grp-pins = <1>;
			qcom,pin-func = <10>;
			label = "tpiu-setb-8";
			setb_8: setb {
				drive-strength = <16>;
				bias-disable;
			};
		};

		tpiu_setb_9 {
			qcom,pins = <&gp 32>;
			qcom,num-grp-pins = <1>;
			qcom,pin-func = <10>;
			label = "tpiu-setb-9";
			setb_9: setb {
				drive-strength = <16>;
				bias-disable;
			};
		};

		tpiu_setb_10 {
			qcom,pins = <&gp 33>;
			qcom,num-grp-pins = <1>;
			qcom,pin-func = <9>;
			label = "tpiu-setb-10";
			setb_10: setb {
				drive-strength = <16>;
				bias-disable;
			};
		};

		tpiu_setb_11 {
			qcom,pins = <&gp 34>;
			qcom,num-grp-pins = <1>;
			qcom,pin-func = <9>;
			label = "tpiu-setb-11";
			setb_11: setb {
				drive-strength = <16>;
				bias-disable;
			};
		};

		tpiu_setb_12 {
			qcom,pins = <&gp 35>;
			qcom,num-grp-pins = <1>;
			qcom,pin-func = <9>;
			label = "tpiu-setb-12";
			setb_12: setb {
				drive-strength = <16>;
				bias-disable;
			};
		};

		tpiu_setb_13 {
			qcom,pins = <&gp 36>;
			qcom,num-grp-pins = <1>;
			qcom,pin-func = <8>;
			label = "tpiu-setb-13";
			setb_13: setb {
				drive-strength = <16>;
				bias-disable;
			};
		};

		tpiu_setb_14 {
			qcom,pins = <&gp 37>;
			qcom,num-grp-pins = <1>;
			qcom,pin-func = <7>;
			label = "tpiu-setb-14";
			setb_14: setb {
				drive-strength = <16>;
				bias-disable;
			};
		};

		tpiu_setb_15 {
			qcom,pins = <&gp 110>;
			qcom,num-grp-pins = <1>;
			qcom,pin-func = <4>;
			label = "tpiu-setb-15";
			setb_15: setb {
				drive-strength = <16>;
				bias-disable;
			};
		};

		tpiu_setb_16 {
			qcom,pins = <&gp 111>;
			qcom,num-grp-pins = <1>;
			qcom,pin-func = <1>;
			label = "tpiu-setb-16";
			setb_16: setb {
				drive-strength = <16>;
				bias-disable;
			};
		};

		tpiu_setb_17 {
			qcom,pins = <&gp 120>;
			qcom,num-grp-pins = <1>;
			qcom,pin-func = <10>;
			label = "tpiu-setb-17";
			setb_17: setb {
				drive-strength = <16>;
				bias-disable;
			};
		};

		tpiu_setb_18 {
			qcom,pins = <&gp 121>;
			qcom,num-grp-pins = <1>;
			qcom,pin-func = <11>;
			label = "tpiu-setb-18";
			setb_18: setb {
				drive-strength = <16>;
				bias-disable;
			};
		};

		uicc-active {
			qcom,pins = <&gp 53>, <&gp 54>;
			qcom,num-grp-pins = <2>;
			qcom,pin-func = <2>;
			label = "uicc-active-pins";

			uicc_active: active {
				drive-strength = <8>;
				bias-disable;
			};
		};

		uicc-sleep {
			qcom,pins = <&gp 53>, <&gp 54>;
			qcom,num-grp-pins = <2>;
			qcom,pin-func = <0>;
			label = "uicc-sleep-pins";

			uicc_sleep: sleep {
				drive-strength = <2>;
				bias-pull-down;
			};
		};

 /* [PLATFORM]-Add-BEGIN by TCTNB.ZXZ, FR-790438, 2014/12/08, config unused gpios for idol3 */
                 unused_gpio_config{
                         qcom,pins = <&gp 11>,<&gp 49>,<&gp 50>,<&gp 51>, <&gp 52>,<&gp 74>, <&gp 77>,
					<&gp 81>,<&gp 95>;
                         qcom,num-grp-pins = <9>;
                         qcom,pin-func = <0>;
                         label = "unused_gpio_config";
                         /* active state */
                         unused_gpio_default: default {
                                 drive-strength = <2>; /* 2 MA */
                                 bias-pull-down;
                         };
                         /*suspended state */
                         unused_gpio_sleep: sleep {
                                 drive-strength = <2>; /* 2 MA */
                                 bias-pull-down;
                         };
                 };
 /* [PLATFORM]-Add-BEGIN by TCTNB.ZXZ */
	        tsl2772x_int_pin { /* [BUFFIX]-Add- by TCTNB.XQJ,PR-886227, 2015/2/2, init int gpio*/
			qcom,pins = <&gp 34>; /*TIANHONGWEI MODIFY*/
			qcom,pin-func = <0>;
			qcom,num-grp-pins = <1>;
			label = "tsl2772x-irq";
			tsl2772x_default: tsl2772x_default {
				drive-strength = <6>;
				bias-pull-up;
			};
			tsl2772x_sleep: tsl2772x_sleep {
				drive-strength = <2>;
				bias-pull-down;
			};
		};

/* [PLATFORM]-Add-BEGIN by TCTNB.Yubin, 2015/02/06, config sim det gpios for idol3 to make sd card det voltage is right */
                 unused_gpio_config2{
                         qcom,pins = <&gp 60>,<&gp 56>;
                         qcom,num-grp-pins = <2>;
                         qcom,pin-func = <1>;
                         label = "simcard_det_pins";
                         /* active state */
                         simcard_det_pins_default: default {
                                 drive-strength = <2>; /* 2 MA */
                                 bias-pull-up;
                         };
                         /*suspended state */
                         simcard_det_pins_sleep: sleep {
                                 drive-strength = <2>; /* 2 MA */
                                 bias-pull-up;
                         };
                 };
/* [PLATFORM]-Add-BEGIN by TCTNB.YuBin */
	};
};
